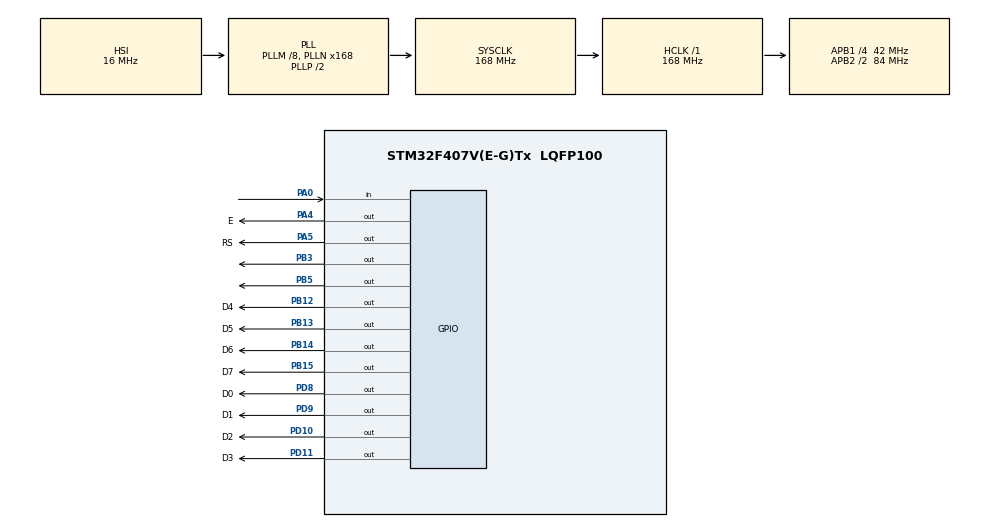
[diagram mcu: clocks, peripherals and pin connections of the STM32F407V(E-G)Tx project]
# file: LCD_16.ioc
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Mcu.Family=STM32F4
Mcu.Name=STM32F407V(E-G)Tx
Mcu.Package=LQFP100
NVIC.PriorityGroup=NVIC_PRIORITYGROUP_4
PA0-WKUP.GPIO_PuPd=GPIO_PULLDOWN
PA0-WKUP.Signal=GPIO_Input
PA4.GPIO_Label=E
PA4.Signal=GPIO_Output
PA5.GPIO_Label=RS
PA5.Signal=GPIO_Output
PB12.GPIO_Label=D4
PB12.Signal=GPIO_Output
PB13.GPIO_Label=D5
PB13.Signal=GPIO_Output
PB14.GPIO_Label=D6
PB14.Signal=GPIO_Output
PB15.GPIO_Label=D7
PB15.Signal=GPIO_Output
PB3.Signal=GPIO_Output
PB5.Signal=GPIO_Output
PD10.GPIO_Label=D2
PD10.Signal=GPIO_Output
PD11.GPIO_Label=D3
PD11.Signal=GPIO_Output
PD8.GPIO_Label=D0
PD8.Signal=GPIO_Output
PD9.GPIO_Label=D1
PD9.Signal=GPIO_Output
ProjectManager.HeapSize=0x200
ProjectManager.StackSize=0x400
ProjectManager.TargetToolchain=MDK-ARM V5.27
RCC.48MHZClocksFreq_Value=84000000
RCC.AHBFreq_Value=168000000
RCC.APB1CLKDivider=RCC_HCLK_DIV4
RCC.APB1Freq_Value=42000000
RCC.APB1TimFreq_Value=84000000
RCC.APB2CLKDivider=RCC_HCLK_DIV2
RCC.APB2Freq_Value=84000000
RCC.APB2TimFreq_Value=168000000
RCC.CortexFreq_Value=168000000
RCC.HCLKFreq_Value=168000000
RCC.HSE_VALUE=25000000
RCC.HSI_VALUE=16000000
RCC.LSE_VALUE=32768
RCC.PLLM=8
RCC.PLLN=168
RCC.SYSCLKFreq_VALUE=168000000
RCC.SYSCLKSource=RCC_SYSCLKSOURCE_PLLCLK
RCC.VCOOutputFreq_Value=336000000
board=custom

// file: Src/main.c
/* USER CODE BEGIN Header */
/**
  ******************************************************************************
  * @file           : main.c
  * @brief          : Main program body
  ******************************************************************************
  * @attention
  *
  * <h2><center>&copy; Copyright (c) 2020 STMicroelectronics.
  * All rights reserved.</center></h2>
  *
  * This software component is licensed by ST under BSD 3-Clause license,
  * the "License"; You may not use this file except in compliance with the
  * License. You may obtain a copy of the License at:
  *                        opensource.org/licenses/BSD-3-Clause
  *
  ******************************************************************************
  */
/* USER CODE END Header */

#include "main.h"

/* USER CODE BEGIN Includes */
#include "STM_MY_LCD16X2.h"
#include <string.h>

/* USER CODE END Includes */

void SystemClock_Config(void);
static void MX_GPIO_Init(void);

int main(void)
{

  /* MCU Configuration--------------------------------------------------------*/

  /* Reset of all peripherals, Initializes the Flash interface and the Systick. */
  HAL_Init();

  /* Configure the system clock */
  SystemClock_Config();

  /* Initialize all configured peripherals */
  MX_GPIO_Init();
  /* USER CODE BEGIN 2 */
	//LCD1602_Begin8BIT(RS_GPIO_Port, RS_Pin, E_Pin, GPIOD, GPIO_PIN_8, GPIO_PIN_9, GPIO_PIN_10, GPIO_PIN_11, GPIOB, GPIO_PIN_12, GPIO_PIN_13, GPIO_PIN_14, GPIO_PIN_15);
	LCD1602_Begin8BIT(RS_GPIO_Port, RS_Pin, E_Pin, D0_GPIO_Port, D0_Pin, D1_Pin, D2_Pin, D3_Pin, D4_GPIO_Port, D4_Pin, D5_Pin, D6_Pin, D7_Pin);

  /* USER CODE END 2 */

  /* Infinite loop */
  while (1)
  {
		if(HAL_GPIO_ReadPin(GPIOA, GPIO_PIN_0))
		{
		LCD1602_1stLine();
		LCD1602_print("123 qwe +- ()=");

		HAL_GPIO_WritePin(GPIOB, GPIO_PIN_5, GPIO_PIN_SET);

		HAL_GPIO_WritePin(GPIOB, GPIO_PIN_3, GPIO_PIN_SET);
		HAL_Delay(5);
		HAL_GPIO_WritePin(GPIOB, GPIO_PIN_3, GPIO_PIN_RESET);
		}
		else
		{
		LCD1602_1stLine();
		LCD1602_print("ABC abc £#$ ");

		HAL_GPIO_WritePin(GPIOB, GPIO_PIN_5, GPIO_PIN_RESET);

		HAL_GPIO_WritePin(GPIOB, GPIO_PIN_3, GPIO_PIN_SET);
		HAL_Delay(5);
		HAL_GPIO_WritePin(GPIOB, GPIO_PIN_3, GPIO_PIN_RESET);
		}

		HAL_Delay(50);

  }
}

void SystemClock_Config(void)
{
  RCC_OscInitTypeDef RCC_OscInitStruct = {0};
  RCC_ClkInitTypeDef RCC_ClkInitStruct = {0};

  /** Configure the main internal regulator output voltage
  */
  __HAL_RCC_PWR_CLK_ENABLE();
  __HAL_PWR_VOLTAGESCALING_CONFIG(PWR_REGULATOR_VOLTAGE_SCALE1);
  /** Initializes the CPU, AHB and APB busses clocks
  */
  RCC_OscInitStruct.OscillatorType = RCC_OSCILLATORTYPE_HSI;
  RCC_OscInitStruct.HSIState = RCC_HSI_ON;
  RCC_OscInitStruct.HSICalibrationValue = RCC_HSICALIBRATION_DEFAULT;
  RCC_OscInitStruct.PLL.PLLState = RCC_PLL_ON;
  RCC_OscInitStruct.PLL.PLLSource = RCC_PLLSOURCE_HSI;
  RCC_OscInitStruct.PLL.PLLM = 8;
  RCC_OscInitStruct.PLL.PLLN = 168;
  RCC_OscInitStruct.PLL.PLLP = RCC_PLLP_DIV2;
  RCC_OscInitStruct.PLL.PLLQ = 4;
  if (HAL_RCC_OscConfig(&RCC_OscInitStruct) != HAL_OK)
  {
    Error_Handler();
  }
  /** Initializes the CPU, AHB and APB busses clocks
  */
  RCC_ClkInitStruct.ClockType = RCC_CLOCKTYPE_HCLK|RCC_CLOCKTYPE_SYSCLK
                              |RCC_CLOCKTYPE_PCLK1|RCC_CLOCKTYPE_PCLK2;
  RCC_ClkInitStruct.SYSCLKSource = RCC_SYSCLKSOURCE_PLLCLK;
  RCC_ClkInitStruct.AHBCLKDivider = RCC_SYSCLK_DIV1;
  RCC_ClkInitStruct.APB1CLKDivider = RCC_HCLK_DIV4;
  RCC_ClkInitStruct.APB2CLKDivider = RCC_HCLK_DIV2;

  if (HAL_RCC_ClockConfig(&RCC_ClkInitStruct, FLASH_LATENCY_5) != HAL_OK)
  {
    Error_Handler();
  }
}

static void MX_GPIO_Init(void)
{
  GPIO_InitTypeDef GPIO_InitStruct = {0};

  /* GPIO Ports Clock Enable */
  __HAL_RCC_GPIOA_CLK_ENABLE();
  __HAL_RCC_GPIOB_CLK_ENABLE();
  __HAL_RCC_GPIOD_CLK_ENABLE();

  /*Configure GPIO pin Output Level */
  HAL_GPIO_WritePin(GPIOA, E_Pin|RS_Pin, GPIO_PIN_RESET);

  /*Configure GPIO pin Output Level */
  HAL_GPIO_WritePin(GPIOB, D4_Pin|D5_Pin|D6_Pin|D7_Pin
                          |GPIO_PIN_3|GPIO_PIN_5, GPIO_PIN_RESET);

  /*Configure GPIO pin Output Level */
  HAL_GPIO_WritePin(GPIOD, D0_Pin|D1_Pin|D2_Pin|D3_Pin, GPIO_PIN_RESET);

  /*Configure GPIO pin : PA0 */
  GPIO_InitStruct.Pin = GPIO_PIN_0;
  GPIO_InitStruct.Mode = GPIO_MODE_INPUT;
  GPIO_InitStruct.Pull = GPIO_PULLDOWN;
  HAL_GPIO_Init(GPIOA, &GPIO_InitStruct);

  /*Configure GPIO pins : E_Pin RS_Pin */
  GPIO_InitStruct.Pin = E_Pin|RS_Pin;
  GPIO_InitStruct.Mode = GPIO_MODE_OUTPUT_PP;
  GPIO_InitStruct.Pull = GPIO_NOPULL;
  GPIO_InitStruct.Speed = GPIO_SPEED_FREQ_LOW;
  HAL_GPIO_Init(GPIOA, &GPIO_InitStruct);

  /*Configure GPIO pins : D4_Pin D5_Pin D6_Pin D7_Pin
                           PB3 PB5 */
  GPIO_InitStruct.Pin = D4_Pin|D5_Pin|D6_Pin|D7_Pin
                          |GPIO_PIN_3|GPIO_PIN_5;
  GPIO_InitStruct.Mode = GPIO_MODE_OUTPUT_PP;
  GPIO_InitStruct.Pull = GPIO_NOPULL;
  GPIO_InitStruct.Speed = GPIO_SPEED_FREQ_LOW;
  HAL_GPIO_Init(GPIOB, &GPIO_InitStruct);

  /*Configure GPIO pins : D0_Pin D1_Pin D2_Pin D3_Pin */
  GPIO_InitStruct.Pin = D0_Pin|D1_Pin|D2_Pin|D3_Pin;
  GPIO_InitStruct.Mode = GPIO_MODE_OUTPUT_PP;
  GPIO_InitStruct.Pull = GPIO_NOPULL;
  GPIO_InitStruct.Speed = GPIO_SPEED_FREQ_LOW;
  HAL_GPIO_Init(GPIOD, &GPIO_InitStruct);

}

void Error_Handler(void)
{
}

/************************ (C) COPYRIGHT STMicroelectronics *****END OF FILE****/
